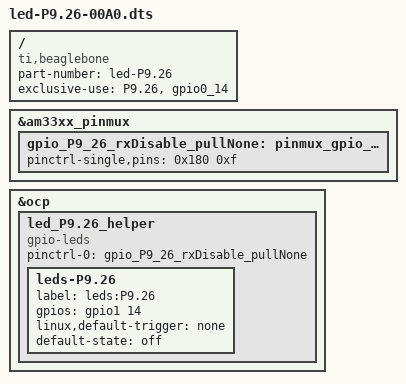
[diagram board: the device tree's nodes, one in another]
/*
* Easy gpio mux control of "P9.26" ("gpio0_14")
*/
/dts-v1/;
/plugin/;

/ {
	compatible = "ti,beaglebone", "ti,beaglebone-black";

	/* identification */
	part-number = "led-P9.26";
	/* version = "00A0"; */

	/* state the resources this cape uses */
	exclusive-use =
		/* the pin header uses */
		"P9.26",

		/* the hardware IP uses */
		"gpio0_14";
	
	
	/* rxDisable_pullNone state */
	fragment@0 {
		target = <&am33xx_pinmux>;
		__overlay__ {
			gpio_P9_26_rxDisable_pullNone: pinmux_gpio_P9.26_rxDisable_pullNone {
				pinctrl-single,pins = <
					0x180 0xf
				>;
			};
		};
	};

	fragment@1 {
		target = <&ocp>;
		__overlay__ {
			led_P9.26_helper {
				compatible = "gpio-leds";
				pinctrl-names = "default";
				pinctrl-0 = <&gpio_P9_26_rxDisable_pullNone>;
				
				leds-P9.26 {
					label = "leds:P9.26";
					gpios = <&gpio1 14 0>;
					linux,default-trigger = "none";
					default-state = "off";
				};
			};
			
		};
	};

};
